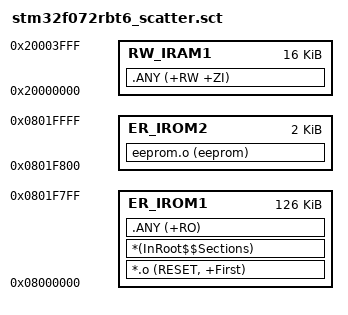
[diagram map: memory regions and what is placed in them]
; *************************************************************
; ***      Custom Scatter-Loading Description File          ***
; *************************************************************

LR_IROM1 0x08000000 0x0001F800  {    ; load region size_region
  ER_IROM1 0x08000000 0x0001F800  {  ; load address = execution address
   *.o (RESET, +First)
   *(InRoot$$Sections)
   .ANY (+RO)
  }
  RW_IRAM1 0x20000000 0x00004000  {  ; RW data
   .ANY (+RW +ZI)
  }
}

LR_IROM2 0x0801F800 0x00000800  {
  ER_IROM2 0x0801F800 0x00000800  {  ; load address = execution address
    eeprom.o (eeprom)
   ;.ANY (+RO)
  }
}

